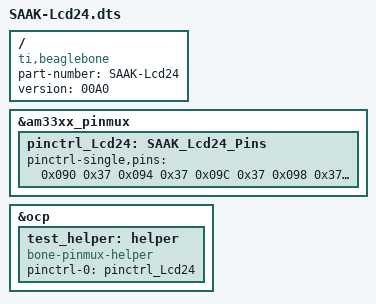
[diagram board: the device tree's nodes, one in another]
/*  
* Copyright (C) 2012 Texas Instruments Incorporated - http://www.ti.com/
*
* This program is free software; you can redistribute it and/or modify
* it under the terms of the GNU General Purpose License Version 2 as
* published by the Free Software Foundation
*
* by Saak Dertadian (s.dertadian@gmail.com)
*
* Cape LCD 2.4' for Beaglebone
* usind Color LCD 240x320 (Newhaven: NHD‐2.4‐240320SF)
*
*/

/dts-v1/;
/plugin/;

/{
	compatible = "ti,beaglebone", "ti,beaglebone-black";
	part-number = "SAAK-Lcd24";
	version = "00A0";

	fragment@0
	{
		target = <&am33xx_pinmux>;
		
		__overlay__
		{
			pinctrl_Lcd24: SAAK_Lcd24_Pins
			{
				pinctrl-single,pins = <

				0x090 0x37  /* P8_07  66 INPUT  MODE7 - D0  */
				0x094 0x37  /* P8_08  67 INPUT  MODE7 - D1  */
				0x09C 0x37  /* P8_09  69 INPUT  MODE7 - D2  */
				0x098 0x37  /* P8_10  68 INPUT  MODE7 - D3  */
				0x034 0x37  /* P8_11  45 INPUT  MODE7 - D4  */
				0x030 0x37  /* P8_12  44 INPUT  MODE7 - D5  */
				0x024 0x37  /* P8_13  23 INPUT  MODE7 - D6  */
				0x028 0x37  /* P8_14  26 INPUT  MODE7 - D7  */

				0x03C 0x37  /* P8_15  47 INPUT  MODE7 - D8  */
				0x038 0x37  /* P8_16  46 INPUT  MODE7 - D9  */
				0x02C 0x37  /* P8_17  27 INPUT  MODE7 - D10 */
				0x08C 0x37  /* P8_18  65 INPUT  MODE7 - D11 */
				0x020 0x37  /* P8_19  22 INPUT  MODE7 - D12 */
				0x07C 0x37  /* P8_26  61 INPUT  MODE7 - D13 */
				0x070 0x37  /* P9_11  30 INPUT  MODE7 - D14 */
				0x1A4 0x37  /* P9_27 115 INPUT  MODE7 - D15 */

				0x040 0x7F  /* P9_15  48 OUTPUT MODE7 - CS  */
				0x044 0x7F  /* P9_23  49 OUTPUT MODE7 - DC  */
				0x048 0x7F  /* P9_14  50 OUTPUT MODE7 - WR  */
				0x04C 0x7F  /* P9_16  51 OUTPUT MODE7 - RD  */
				0x078 0x7F  /* P9_12  60 OUTPUT MODE7 - RS  */
					
				/* OUTPUT  GPIO(mode7) 0x07 pulldown, 0x17 pullup, 0x?f no pullup/down */
				/* INPUT   GPIO(mode7) 0x27 pulldown, 0x37 pullup, 0x?f no pullup/down */

				>;
			};
		};
	};

	fragment@1
	{
		target = <&ocp>;
		__overlay__
		{
			test_helper: helper
			{
				compatible = "bone-pinmux-helper";
				pinctrl-names = "default";
				pinctrl-0 = <&pinctrl_Lcd24>;
				status = "okay";
			};
		};
	};
};
